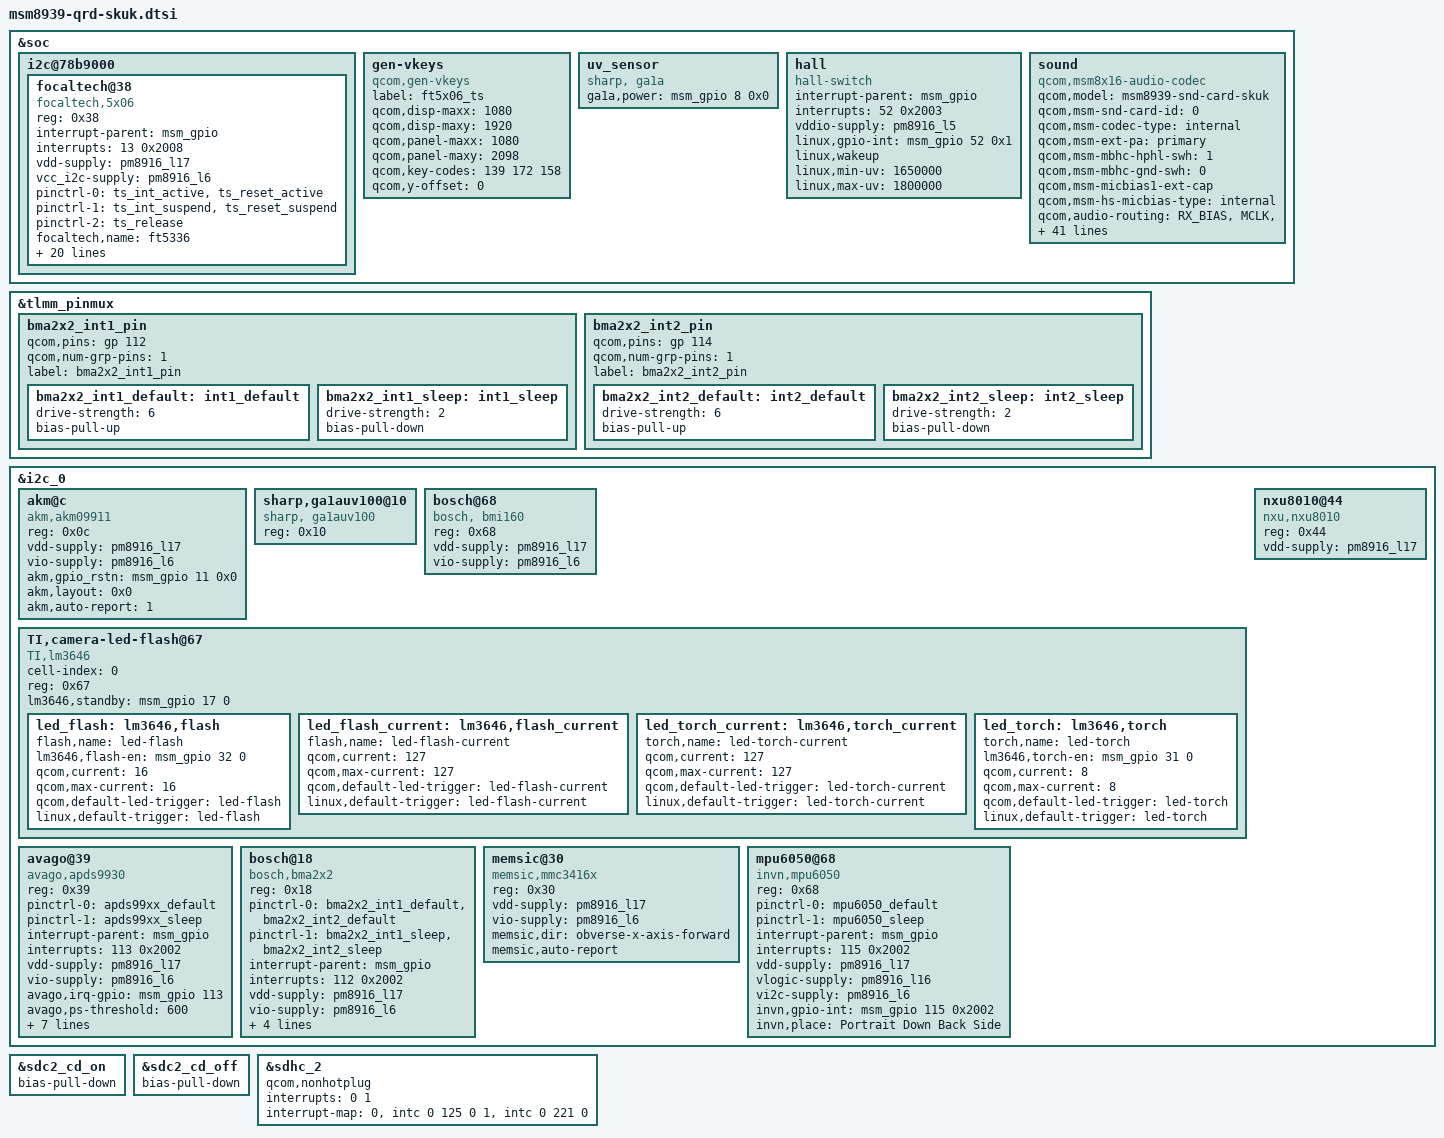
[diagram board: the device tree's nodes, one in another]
/* Copyright (c) 2014-2015, The Linux Foundation. All rights reserved.
 *
 * This program is free software; you can redistribute it and/or modify
 * it under the terms of the GNU General Public License version 2 and
 * only version 2 as published by the Free Software Foundation.
 *
 * This program is distributed in the hope that it will be useful,
 * but WITHOUT ANY WARRANTY; without even the implied warranty of
 * MERCHANTABILITY or FITNESS FOR A PARTICULAR PURPOSE.  See the
 * GNU General Public License for more details.
 */

#include "msm8939-qrd.dtsi"
#include "msm8939-camera-sensor-qrd.dtsi"

&soc {
	i2c@78b9000 { /* BLSP1 QUP5 */
		focaltech@38 {
			compatible = "focaltech,5x06";
			reg = <0x38>;
			interrupt-parent = <&msm_gpio>;
			interrupts = <13 0x2008>;
			vdd-supply = <&pm8916_l17>;
			vcc_i2c-supply = <&pm8916_l6>;
			/* pins used by touchscreen */
			pinctrl-names = "pmx_ts_active","pmx_ts_suspend","pmx_ts_release";
			pinctrl-0 = <&ts_int_active &ts_reset_active>;
			pinctrl-1 = <&ts_int_suspend &ts_reset_suspend>;
			pinctrl-2 = <&ts_release>;
			focaltech,name = "ft5336";
			focaltech,family-id = <0x14>;
			focaltech,reset-gpio = <&msm_gpio 12 0x0>;
			focaltech,irq-gpio = <&msm_gpio 13 0x2008>;
			focaltech,display-coords = <0 0 1080 1920>;
			focaltech,panel-coords = <0 0 1080 2098>;
			focaltech,button-map= <139 102 158>;
			focaltech,no-force-update;
			focaltech,i2c-pull-up;
			focaltech,group-id = <1>;
			focaltech,hard-reset-delay-ms = <20>;
			focaltech,soft-reset-delay-ms = <200>;
			focaltech,num-max-touches = <5>;
			focaltech,fw-delay-aa-ms = <30>;
			focaltech,fw-delay-55-ms = <30>;
			focaltech,fw-upgrade-id1 = <0x11>;
			focaltech,fw-upgrade-id2 = <0x11>;
			focaltech,fw-delay-readid-ms = <10>;
			focaltech,fw-delay-era-flsh-ms = <2000>;
			focaltech,fw-auto-cal;
			focaltech,ignore-id-check;
		};
	};

	gen-vkeys {
		compatible = "qcom,gen-vkeys";
		label = "ft5x06_ts";
		qcom,disp-maxx = <1080>;
		qcom,disp-maxy = <1920>;
		qcom,panel-maxx = <1080>;
		qcom,panel-maxy = <2098>;
		qcom,key-codes = <139 172 158>;
		qcom,y-offset = <0>;
	};

//add by shuaitao 2015.7.30 begin
        uv_sensor {
                compatible = "sharp, ga1a";
                ga1a,power = <&msm_gpio 8 0x0>;
        };

        hall {
                compatible = "hall-switch";
                interrupt-parent = <&msm_gpio>;
                interrupts = <52 0x2003>;
                vddio-supply = <&pm8916_l5>;
                linux,gpio-int = <&msm_gpio 52 0x1>;
                linux,wakeup;
                linux,min-uv = <1650000>;
                linux,max-uv = <1800000>;
        };
//add by shuaitao 2015.7.30 end

	sound {
		compatible = "qcom,msm8x16-audio-codec";
		qcom,model = "msm8939-snd-card-skuk";
		qcom,msm-snd-card-id = <0>;
		qcom,msm-codec-type = "internal";
		qcom,msm-ext-pa = "primary";
		qcom,msm-mbhc-hphl-swh = <1>;
		qcom,msm-mbhc-gnd-swh = <0>;
		qcom,msm-micbias1-ext-cap;
		qcom,msm-hs-micbias-type = "internal";
		qcom,audio-routing =
			"RX_BIAS", "MCLK",
			"SPK_RX_BIAS", "MCLK",
			"INT_LDO_H", "MCLK",
			"MIC BIAS External", "Handset Mic",
			"MIC BIAS Internal2", "Headset Mic",
			"MIC BIAS External", "Secondary Mic",
			"AMIC1", "MIC BIAS External",
			"AMIC2", "MIC BIAS Internal2",
			"AMIC3", "MIC BIAS External";
		pinctrl-names = "cdc_lines_act",
				"cdc_lines_sus";
		pinctrl-0 = <&cdc_pdm_lines_act>;
		pinctrl-1 = <&cdc_pdm_lines_sus>;
		asoc-platform = <&pcm0>, <&pcm1>, <&voip>, <&voice>,
				<&loopback>, <&compress>, <&hostless>,
				<&afe>, <&lsm>, <&routing>, <&lpa>;
		asoc-platform-names = "msm-pcm-dsp.0", "msm-pcm-dsp.1",
				"msm-voip-dsp", "msm-pcm-voice", "msm-pcm-loopback",
				"msm-compress-dsp", "msm-pcm-hostless", "msm-pcm-afe",
				"msm-lsm-client", "msm-pcm-routing", "msm-pcm-lpa";
		asoc-cpu = <&dai_pri_auxpcm>, <&dai_hdmi>, <&dai_mi2s0>, <&dai_mi2s1>,
				<&dai_mi2s2>, <&dai_mi2s3>, <&sb_0_rx>, <&sb_0_tx>,
				<&sb_1_rx>, <&sb_1_tx>, <&sb_3_rx>, <&sb_3_tx>,
				<&sb_4_rx>, <&sb_4_tx>, <&sb_5_tx>, <&bt_sco_rx>,
				<&bt_sco_tx>, <&int_fm_rx>, <&int_fm_tx>, <&afe_pcm_rx>,
				<&afe_pcm_tx>, <&afe_proxy_rx>, <&afe_proxy_tx>,
				<&incall_record_rx>, <&incall_record_tx>, <&incall_music_rx>,
				<&incall_music_2_rx>;
		asoc-cpu-names = "msm-dai-q6-auxpcm.1", "msm-dai-q6-hdmi.8", "msm-dai-q6-mi2s.0",
				"msm-dai-q6-mi2s.1", "msm-dai-q6-mi2s.2",
				"msm-dai-q6-mi2s.3", "msm-dai-q6-dev.16384",
				"msm-dai-q6-dev.16385", "msm-dai-q6-dev.16386",
				"msm-dai-q6-dev.16387", "msm-dai-q6-dev.16390",
				"msm-dai-q6-dev.16391", "msm-dai-q6-dev.16392",
				"msm-dai-q6-dev.16393", "msm-dai-q6-dev.16395",
				"msm-dai-q6-dev.12288", "msm-dai-q6-dev.12289",
				"msm-dai-q6-dev.12292", "msm-dai-q6-dev.12293",
				"msm-dai-q6-dev.224", "msm-dai-q6-dev.225",
				"msm-dai-q6-dev.241", "msm-dai-q6-dev.240",
				"msm-dai-q6-dev.32771", "msm-dai-q6-dev.32772",
				"msm-dai-q6-dev.32773", "msm-dai-q6-dev.32770";
		asoc-codec = <&stub_codec>, <&pm8916_tombak_dig>;
		asoc-codec-names = "msm-stub-codec.1", "tombak_codec";
	};
};


&tlmm_pinmux {
	bma2x2_int1_pin {
		qcom,pins = <&gp 112>;
		qcom,num-grp-pins = <1>;
		label = "bma2x2_int1_pin";
		bma2x2_int1_default: int1_default {
			  drive-strength = <6>;
			  bias-pull-up;
		};
		bma2x2_int1_sleep: int1_sleep {
			  drive-strength = <2>;
			  bias-pull-down;
		};
	};

	bma2x2_int2_pin {
		qcom,pins = <&gp 114>;
		qcom,num-grp-pins = <1>;
		label = "bma2x2_int2_pin";
		bma2x2_int2_default: int2_default {
			  drive-strength = <6>;
			  bias-pull-up;
		};
		bma2x2_int2_sleep: int2_sleep {
			  drive-strength = <2>;
			  bias-pull-down;
		};
	};
};

&i2c_0 { /* BLSP1 QUP2 */

//add by shuaitao 2015.7.30 begin
	akm@c {
                compatible = "akm,akm09911";
                reg = <0x0c>;
                vdd-supply = <&pm8916_l17>;
                vio-supply = <&pm8916_l6>;
                akm,gpio_rstn = <&msm_gpio 11 0x0>;
                akm,layout = <0x0>;
                akm,auto-report = <1>;
        };

        sharp,ga1auv100@10 {
                compatible = "sharp, ga1auv100";
                reg = <0x10>;
        };

	bosch@68 {
                compatible = "bosch, bmi160";
                reg = <0x68>;
                vdd-supply = <&pm8916_l17>;
                vio-supply = <&pm8916_l6>;
        };

        TI,camera-led-flash@67 {
                cell-index = <0>;
                compatible = "TI,lm3646";
                reg = <0x67>;
                lm3646,standby = <&msm_gpio 17 0>;
                led_flash: lm3646,flash {
                        flash,name = "led-flash";
                        lm3646,flash-en = <&msm_gpio 32 0>;
                        qcom,current = <16>;
                        qcom,max-current = <16>;
                        qcom,default-led-trigger = "led-flash";
                        linux,default-trigger = "led-flash";
                };
		led_flash_current: lm3646,flash_current {
                        flash,name = "led-flash-current";
                        qcom,current = <127>;
                        qcom,max-current = <127>;
                        qcom,default-led-trigger = "led-flash-current";
                        linux,default-trigger = "led-flash-current";
                };
                led_torch_current: lm3646,torch_current {
                        torch,name = "led-torch-current";
                        qcom,current = <127>;
                        qcom,max-current = <127>;
                        qcom,default-led-trigger = "led-torch-current";
                        linux,default-trigger = "led-torch-current";
                };
                led_torch: lm3646,torch {
                        torch,name = "led-torch";
                        lm3646,torch-en = <&msm_gpio 31 0>;
                        qcom,current = <8>;
                        qcom,max-current = <8>;
                        qcom,default-led-trigger = "led-torch";
                        linux,default-trigger = "led-torch";
                };
        };

	nxu8010@44 {
                compatible = "nxu,nxu8010";
                reg = <0x44>;
                vdd-supply = <&pm8916_l17>;
        };
//add by shuaitao 2015.7.30 end

	avago@39 { /* Ambient light and proximity sensor */
		compatible = "avago,apds9930";
		reg = <0x39>;
		pinctrl-names = "default","sleep";
		pinctrl-0 = <&apds99xx_default>;
		pinctrl-1 = <&apds99xx_sleep>;
		interrupt-parent = <&msm_gpio>;
		interrupts = <113 0x2002>;
		vdd-supply = <&pm8916_l17>;
		vio-supply = <&pm8916_l6>;
		avago,irq-gpio = <&msm_gpio 113 0x2002>;
		avago,ps-threshold = <600>;
		avago,ps-hysteresis-threshold = <500>;
		avago,ps-pulse = <8>;
		avago,ps-pgain = <0>;
		avago,als-B = <186>;
		avago,als-C = <75>;
		avago,als-D = <129>;
		avago,ga-value = <560>;
	};

	bosch@18 { /* Accelerometer sensor */
		compatible = "bosch,bma2x2";
		reg = <0x18>;
		pinctrl-names = "bma_default","bma_sleep";
		pinctrl-0 = <&bma2x2_int1_default &bma2x2_int2_default>;
		pinctrl-1 = <&bma2x2_int1_sleep &bma2x2_int2_sleep>;
		interrupt-parent = <&msm_gpio>;
		interrupts = <112 0x2002>;
		vdd-supply = <&pm8916_l17>;
		vio-supply = <&pm8916_l6>;
		bosch,init-interval = <200>;
		bosch,place = <2>;
		bosch,gpio-int1 = <&msm_gpio 112 0x2002>;
		bosch,gpio-int2 = <&msm_gpio 114 0x2002>;
	};

	memsic@30 { /* Magnetic field sensor */
		compatible = "memsic,mmc3416x";
		reg = <0x30>;
		vdd-supply = <&pm8916_l17>;
		vio-supply = <&pm8916_l6>;
		memsic,dir = "obverse-x-axis-forward";
		memsic,auto-report;
	};

	mpu6050@68 { /* Gyroscope and accelerometer sensor combo */
		compatible = "invn,mpu6050";
		reg = <0x68>;
		pinctrl-names = "mpu_default","mpu_sleep";
		pinctrl-0 = <&mpu6050_default>;
		pinctrl-1 = <&mpu6050_sleep>;
		interrupt-parent = <&msm_gpio>;
		interrupts = <115 0x2002>;
		vdd-supply = <&pm8916_l17>;
		vlogic-supply = <&pm8916_l16>;
		vi2c-supply = <&pm8916_l6>;
		invn,gpio-int = <&msm_gpio 115 0x2002>;
		invn,place = "Portrait Down Back Side";
	};
};

&sdc2_cd_on {
	/delete-property/ bias-pull-up;
	bias-pull-down;
};

&sdc2_cd_off {
	/delete-property/ bias-disable;
	bias-pull-down;
};

&sdhc_2 {
	qcom,nonhotplug;
	interrupts = <0 1>;
	interrupt-map = <0 &intc 0 125 0
		1 &intc 0 221 0>;
	interrupt-names = "hc_irq", "pwr_irq";
	/delete-property/ cd-gpios;
};
/*
&mdss_mdp {
	qcom,mdss-pref-prim-intf = "dsi";
};

&pmx_mdss {
	qcom,num-grp-pins = <2>;
	qcom,pins = <&gp 1>, <&gp 25>;
};

&mdss_dsi0 {
	pinctrl-names = "mdss_default", "mdss_sleep";
	pinctrl-0 = <&mdss_dsi_active>;
	pinctrl-1 = <&mdss_dsi_suspend>;

	qcom,platform-reset-gpio = <&msm_gpio 25 0>;
	qcom,platform-bklight-en-gpio = <&msm_gpio 1 0>;
};
*/
